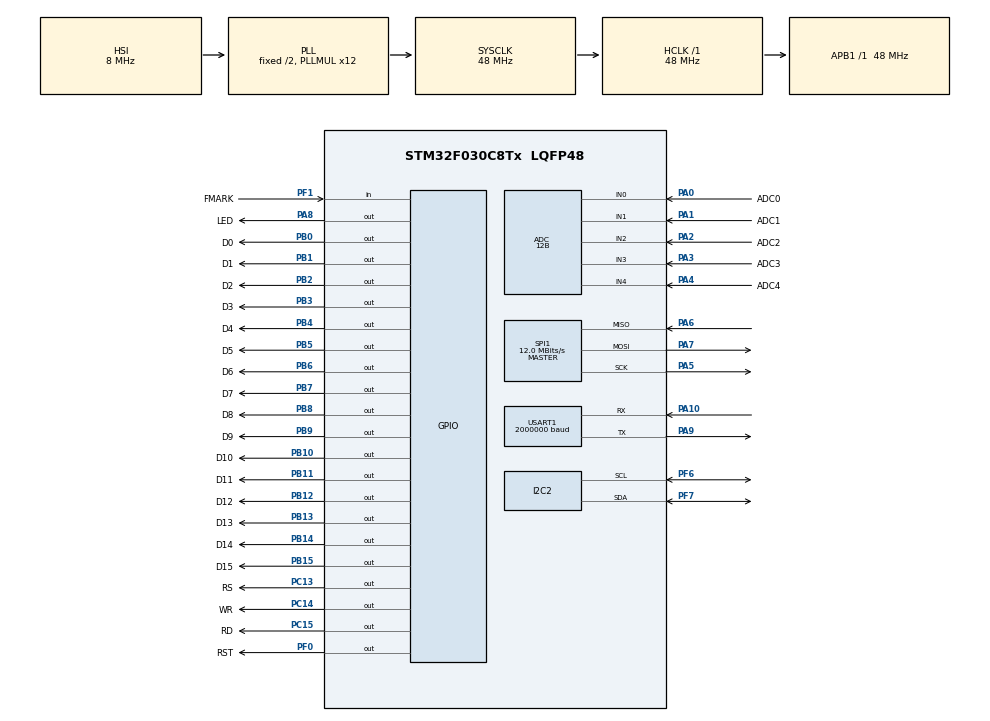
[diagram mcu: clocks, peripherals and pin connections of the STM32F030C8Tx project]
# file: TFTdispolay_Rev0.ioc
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ADC.ClockPrescaler=ADC_CLOCK_ASYNC_DIV1
ADC.ContinuousConvMode=DISABLE
ADC.Resolution=ADC_RESOLUTION_12B
ADC.SamplingTime=ADC_SAMPLETIME_28CYCLES_5
FATFS._FS_TIMEOUT=1000
FATFS._MAX_SS=1024
FATFS._USE_LFN=1
I2C2.Timing=0x20303E5D
Mcu.Family=STM32F0
Mcu.Name=STM32F030C8Tx
Mcu.Package=LQFP48
PA0.GPIO_Label=ADC0
PA0.Mode=IN0
PA0.Signal=ADC_IN0
PA1.GPIO_Label=ADC1
PA1.Mode=IN1
PA1.Signal=ADC_IN1
PA10.GPIO_ModeDefaultPP=GPIO_MODE_AF_PP
PA10.GPIO_PuPd=GPIO_NOPULL
PA10.GPIO_Speed=GPIO_SPEED_FREQ_HIGH
PA10.Mode=Asynchronous
PA10.Signal=USART1_RX
PA13.GPIO_Label=SWDIO
PA13.Signal=SYS_SWDIO
PA2.GPIO_Label=ADC2
PA2.Mode=IN2
PA2.Signal=ADC_IN2
PA3.GPIO_Label=ADC3
PA3.Mode=IN3
PA3.Signal=ADC_IN3
PA4.GPIO_Label=ADC4
PA4.Mode=IN4
PA4.Signal=ADC_IN4
PA5.GPIO_Mode=GPIO_MODE_AF_PP
PA5.GPIO_PuPd=GPIO_NOPULL
PA5.GPIO_Speed=GPIO_SPEED_FREQ_HIGH
PA5.Mode=Full_Duplex_Master
PA5.Signal=SPI1_SCK
PA6.GPIO_Mode=GPIO_MODE_AF_PP
PA6.GPIO_PuPd=GPIO_NOPULL
PA6.GPIO_Speed=GPIO_SPEED_FREQ_HIGH
PA6.Mode=Full_Duplex_Master
PA6.Signal=SPI1_MISO
PA7.GPIO_Mode=GPIO_MODE_AF_PP
PA7.GPIO_PuPd=GPIO_NOPULL
PA7.GPIO_Speed=GPIO_SPEED_FREQ_HIGH
PA7.Mode=Full_Duplex_Master
PA7.Signal=SPI1_MOSI
PA8.GPIO_Label=LED
PA8.GPIO_ModeDefaultOutputPP=GPIO_MODE_OUTPUT_OD
PA8.GPIO_PuPd=GPIO_PULLUP
PA8.GPIO_Speed=GPIO_SPEED_FREQ_HIGH
PA8.PinState=GPIO_PIN_RESET
PA8.Signal=GPIO_Output
PA9.GPIO_ModeDefaultPP=GPIO_MODE_AF_PP
PA9.GPIO_PuPd=GPIO_NOPULL
PA9.GPIO_Speed=GPIO_SPEED_FREQ_HIGH
PA9.Mode=Asynchronous
PA9.Signal=USART1_TX
PB0.GPIO_Label=D0
PB0.GPIO_PuPd=GPIO_NOPULL
PB0.GPIO_Speed=GPIO_SPEED_FREQ_HIGH
PB0.Signal=GPIO_Output
PB1.GPIO_Label=D1
PB1.GPIO_PuPd=GPIO_NOPULL
PB1.GPIO_Speed=GPIO_SPEED_FREQ_HIGH
PB1.Signal=GPIO_Output
PB10.GPIO_Label=D10
PB10.GPIO_ModeDefaultOutputPP=GPIO_MODE_OUTPUT_OD
PB10.GPIO_PuPd=GPIO_NOPULL
PB10.GPIO_Speed=GPIO_SPEED_FREQ_HIGH
PB10.Signal=GPIO_Output
PB11.GPIO_Label=D11
PB11.GPIO_Speed=GPIO_SPEED_FREQ_HIGH
PB11.Signal=GPIO_Output
PB12.GPIO_Label=D12
PB12.GPIO_Speed=GPIO_SPEED_FREQ_HIGH
PB12.Signal=GPIO_Output
PB13.GPIO_Label=D13
PB13.GPIO_Speed=GPIO_SPEED_FREQ_HIGH
PB13.Signal=GPIO_Output
PB14.GPIO_Label=D14
PB14.GPIO_Speed=GPIO_SPEED_FREQ_HIGH
PB14.Signal=GPIO_Output
PB15.GPIO_Label=D15
PB15.GPIO_Speed=GPIO_SPEED_FREQ_HIGH
PB15.Signal=GPIO_Output
PB2.GPIO_Label=D2
PB2.GPIO_PuPd=GPIO_NOPULL
PB2.GPIO_Speed=GPIO_SPEED_FREQ_HIGH
PB2.Signal=GPIO_Output
PB3.GPIO_Label=D3
PB3.GPIO_PuPd=GPIO_NOPULL
PB3.GPIO_Speed=GPIO_SPEED_FREQ_HIGH
PB3.Signal=GPIO_Output
PB4.GPIO_Label=D4
PB4.GPIO_PuPd=GPIO_NOPULL
PB4.GPIO_Speed=GPIO_SPEED_FREQ_HIGH
PB4.Signal=GPIO_Output
PB5.GPIO_Label=D5
PB5.GPIO_PuPd=GPIO_NOPULL
PB5.GPIO_Speed=GPIO_SPEED_FREQ_HIGH
PB5.Signal=GPIO_Output
PB6.GPIO_FM6=__NULL
PB6.GPIO_Label=D6
PB6.GPIO_PuPd=GPIO_NOPULL
PB6.GPIO_Speed=GPIO_SPEED_FREQ_HIGH
PB6.Signal=GPIO_Output
PB7.GPIO_Label=D7
PB7.GPIO_PuPd=GPIO_NOPULL
PB7.GPIO_Speed=GPIO_SPEED_FREQ_HIGH
PB7.Signal=GPIO_Output
PB8.GPIO_Label=D8
PB8.GPIO_PuPd=GPIO_NOPULL
PB8.GPIO_Speed=GPIO_SPEED_FREQ_HIGH
PB8.Signal=GPIO_Output
PB9.GPIO_Label=D9
PB9.GPIO_PuPd=GPIO_NOPULL
PB9.GPIO_Speed=GPIO_SPEED_FREQ_HIGH
PB9.Signal=GPIO_Output
PC13.GPIO_Label=RS
PC13.GPIO_PuPd=GPIO_PULLUP
PC13.Signal=GPIO_Output
PC14-OSC32_IN.GPIO_Label=WR
PC14-OSC32_IN.GPIO_PuPd=GPIO_PULLUP
PC14-OSC32_IN.Signal=GPIO_Output
PC15-OSC32_OUT.GPIO_Label=RD
PC15-OSC32_OUT.GPIO_PuPd=GPIO_PULLUP
PC15-OSC32_OUT.Signal=GPIO_Output
PF0-OSC_IN.GPIO_Label=RST
PF0-OSC_IN.GPIO_PuPd=GPIO_PULLUP
PF0-OSC_IN.GPIO_Speed=GPIO_SPEED_FREQ_HIGH
PF0-OSC_IN.Signal=GPIO_Output
PF1-OSC_OUT.GPIO_Label=FMARK
PF1-OSC_OUT.Signal=GPIO_Input
PF6.Mode=I2C
PF6.Signal=I2C2_SCL
PF7.Mode=I2C
PF7.Signal=I2C2_SDA
ProjectManager.HeapSize=0x200
ProjectManager.StackSize=0x400
ProjectManager.TargetToolchain=STM32CubeIDE
RCC.AHBFreq_Value=48000000
RCC.APB1Freq_Value=48000000
RCC.APB1TimFreq_Value=48000000
RCC.HCLKFreq_Value=48000000
RCC.PLLMUL=RCC_PLL_MUL12
RCC.SYSCLKFreq_VALUE=48000000
RCC.SYSCLKSource=RCC_SYSCLKSOURCE_PLLCLK
SPI1.BaudRatePrescaler=SPI_BAUDRATEPRESCALER_4
SPI1.CalculateBaudRate=12.0 MBits/s
SPI1.DataSize=SPI_DATASIZE_8BIT
SPI1.Direction=SPI_DIRECTION_2LINES
SPI1.Mode=SPI_MODE_MASTER
SPI1.VirtualType=VM_MASTER
USART1.BaudRate=2000000
USART1.OverrunDisableParam=ADVFEATURE_OVERRUN_DISABLE
USART1.VirtualMode-Asynchronous=VM_ASYNC
VP_FATFS_VS_Generic.Mode=User_defined
board=custom

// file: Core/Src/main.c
/* USER CODE BEGIN Header */
/**
  ******************************************************************************
  * @file           : main.c
  * @brief          : Main program body
  ******************************************************************************
  * @attention
  *
  * Copyright (c) 2023 STMicroelectronics.
  * All rights reserved.
  *
  * This software is licensed under terms that can be found in the LICENSE file
  * in the root directory of this software component.
  * If no LICENSE file comes with this software, it is provided AS-IS.
  *
  ******************************************************************************
  */
/* USER CODE END Header */
#include "main.h"
#include "fatfs.h"

/* USER CODE BEGIN Includes */
#include "app.h"
/* USER CODE END Includes */

ADC_HandleTypeDef hadc;

I2C_HandleTypeDef hi2c2;

SPI_HandleTypeDef hspi1;

UART_HandleTypeDef huart1;

void SystemClock_Config(void);
static void MX_GPIO_Init(void);
static void MX_ADC_Init(void);
static void MX_SPI1_Init(void);
static void MX_USART1_UART_Init(void);
static void MX_I2C2_Init(void);

int main(void)
{

  /* MCU Configuration--------------------------------------------------------*/

  /* Reset of all peripherals, Initializes the Flash interface and the Systick. */
  HAL_Init();

  /* Configure the system clock */
  SystemClock_Config();

  /* Initialize all configured peripherals */
  MX_GPIO_Init();
  MX_ADC_Init();
  MX_SPI1_Init();
  MX_USART1_UART_Init();
  MX_FATFS_Init();
  MX_I2C2_Init();
  /* USER CODE BEGIN 2 */

	HAL_GPIO_WritePin(LED_GPIO_Port, LED_Pin, GPIO_PIN_RESET);
	HAL_Delay(200);
	HAL_GPIO_WritePin(LED_GPIO_Port, LED_Pin, GPIO_PIN_SET);
	HAL_Delay(200);
	HAL_GPIO_WritePin(LED_GPIO_Port, LED_Pin, GPIO_PIN_RESET);
	HAL_Delay(200);
	HAL_GPIO_WritePin(LED_GPIO_Port, LED_Pin, GPIO_PIN_SET);
	HAL_Delay(200);

	app_init();
	app_loop();

  /* USER CODE END 2 */

  /* Infinite loop */
  while (1)
  {

  }
}

void SystemClock_Config(void)
{
  RCC_OscInitTypeDef RCC_OscInitStruct = {0};
  RCC_ClkInitTypeDef RCC_ClkInitStruct = {0};
  RCC_PeriphCLKInitTypeDef PeriphClkInit = {0};

  /** Initializes the RCC Oscillators according to the specified parameters
  * in the RCC_OscInitTypeDef structure.
  */
  RCC_OscInitStruct.OscillatorType = RCC_OSCILLATORTYPE_HSI|RCC_OSCILLATORTYPE_HSI14;
  RCC_OscInitStruct.HSIState = RCC_HSI_ON;
  RCC_OscInitStruct.HSI14State = RCC_HSI14_ON;
  RCC_OscInitStruct.HSICalibrationValue = RCC_HSICALIBRATION_DEFAULT;
  RCC_OscInitStruct.HSI14CalibrationValue = 16;
  RCC_OscInitStruct.PLL.PLLState = RCC_PLL_ON;
  RCC_OscInitStruct.PLL.PLLSource = RCC_PLLSOURCE_HSI;
  RCC_OscInitStruct.PLL.PLLMUL = RCC_PLL_MUL12;
  RCC_OscInitStruct.PLL.PREDIV = RCC_PREDIV_DIV1;
  if (HAL_RCC_OscConfig(&RCC_OscInitStruct) != HAL_OK)
  {
    Error_Handler();
  }

  /** Initializes the CPU, AHB and APB buses clocks
  */
  RCC_ClkInitStruct.ClockType = RCC_CLOCKTYPE_HCLK|RCC_CLOCKTYPE_SYSCLK
                              |RCC_CLOCKTYPE_PCLK1;
  RCC_ClkInitStruct.SYSCLKSource = RCC_SYSCLKSOURCE_PLLCLK;
  RCC_ClkInitStruct.AHBCLKDivider = RCC_SYSCLK_DIV1;
  RCC_ClkInitStruct.APB1CLKDivider = RCC_HCLK_DIV1;

  if (HAL_RCC_ClockConfig(&RCC_ClkInitStruct, FLASH_LATENCY_1) != HAL_OK)
  {
    Error_Handler();
  }
  PeriphClkInit.PeriphClockSelection = RCC_PERIPHCLK_USART1;
  PeriphClkInit.Usart1ClockSelection = RCC_USART1CLKSOURCE_PCLK1;
  if (HAL_RCCEx_PeriphCLKConfig(&PeriphClkInit) != HAL_OK)
  {
    Error_Handler();
  }
}

static void MX_ADC_Init(void)
{

  ADC_ChannelConfTypeDef sConfig = {0};

  /** Configure the global features of the ADC (Clock, Resolution, Data Alignment and number of conversion)
  */
  hadc.Instance = ADC1;
  hadc.Init.ClockPrescaler = ADC_CLOCK_ASYNC_DIV1;
  hadc.Init.Resolution = ADC_RESOLUTION_12B;
  hadc.Init.DataAlign = ADC_DATAALIGN_RIGHT;
  hadc.Init.ScanConvMode = ADC_SCAN_DIRECTION_FORWARD;
  hadc.Init.EOCSelection = ADC_EOC_SINGLE_CONV;
  hadc.Init.LowPowerAutoWait = DISABLE;
  hadc.Init.LowPowerAutoPowerOff = DISABLE;
  hadc.Init.ContinuousConvMode = DISABLE;
  hadc.Init.DiscontinuousConvMode = DISABLE;
  hadc.Init.ExternalTrigConv = ADC_SOFTWARE_START;
  hadc.Init.ExternalTrigConvEdge = ADC_EXTERNALTRIGCONVEDGE_NONE;
  hadc.Init.DMAContinuousRequests = DISABLE;
  hadc.Init.Overrun = ADC_OVR_DATA_PRESERVED;
  if (HAL_ADC_Init(&hadc) != HAL_OK)
  {
    Error_Handler();
  }

  /** Configure for the selected ADC regular channel to be converted.
  */
  sConfig.Channel = ADC_CHANNEL_0;
  sConfig.Rank = ADC_RANK_CHANNEL_NUMBER;
  sConfig.SamplingTime = ADC_SAMPLETIME_28CYCLES_5;
  if (HAL_ADC_ConfigChannel(&hadc, &sConfig) != HAL_OK)
  {
    Error_Handler();
  }

  /** Configure for the selected ADC regular channel to be converted.
  */
  sConfig.Channel = ADC_CHANNEL_1;
  if (HAL_ADC_ConfigChannel(&hadc, &sConfig) != HAL_OK)
  {
    Error_Handler();
  }

  /** Configure for the selected ADC regular channel to be converted.
  */
  sConfig.Channel = ADC_CHANNEL_2;
  if (HAL_ADC_ConfigChannel(&hadc, &sConfig) != HAL_OK)
  {
    Error_Handler();
  }

  /** Configure for the selected ADC regular channel to be converted.
  */
  sConfig.Channel = ADC_CHANNEL_3;
  if (HAL_ADC_ConfigChannel(&hadc, &sConfig) != HAL_OK)
  {
    Error_Handler();
  }

  /** Configure for the selected ADC regular channel to be converted.
  */
  sConfig.Channel = ADC_CHANNEL_4;
  if (HAL_ADC_ConfigChannel(&hadc, &sConfig) != HAL_OK)
  {
    Error_Handler();
  }

}

static void MX_I2C2_Init(void)
{

  hi2c2.Instance = I2C2;
  hi2c2.Init.Timing = 0x20303E5D;
  hi2c2.Init.OwnAddress1 = 0;
  hi2c2.Init.AddressingMode = I2C_ADDRESSINGMODE_7BIT;
  hi2c2.Init.DualAddressMode = I2C_DUALADDRESS_DISABLE;
  hi2c2.Init.OwnAddress2 = 0;
  hi2c2.Init.OwnAddress2Masks = I2C_OA2_NOMASK;
  hi2c2.Init.GeneralCallMode = I2C_GENERALCALL_DISABLE;
  hi2c2.Init.NoStretchMode = I2C_NOSTRETCH_DISABLE;
  if (HAL_I2C_Init(&hi2c2) != HAL_OK)
  {
    Error_Handler();
  }

  /** Configure Analogue filter
  */
  if (HAL_I2CEx_ConfigAnalogFilter(&hi2c2, I2C_ANALOGFILTER_ENABLE) != HAL_OK)
  {
    Error_Handler();
  }

  /** Configure Digital filter
  */
  if (HAL_I2CEx_ConfigDigitalFilter(&hi2c2, 0) != HAL_OK)
  {
    Error_Handler();
  }

}

static void MX_SPI1_Init(void)
{

  /* SPI1 parameter configuration*/
  hspi1.Instance = SPI1;
  hspi1.Init.Mode = SPI_MODE_MASTER;
  hspi1.Init.Direction = SPI_DIRECTION_2LINES;
  hspi1.Init.DataSize = SPI_DATASIZE_8BIT;
  hspi1.Init.CLKPolarity = SPI_POLARITY_LOW;
  hspi1.Init.CLKPhase = SPI_PHASE_1EDGE;
  hspi1.Init.NSS = SPI_NSS_SOFT;
  hspi1.Init.BaudRatePrescaler = SPI_BAUDRATEPRESCALER_4;
  hspi1.Init.FirstBit = SPI_FIRSTBIT_MSB;
  hspi1.Init.TIMode = SPI_TIMODE_DISABLE;
  hspi1.Init.CRCCalculation = SPI_CRCCALCULATION_DISABLE;
  hspi1.Init.CRCPolynomial = 7;
  hspi1.Init.CRCLength = SPI_CRC_LENGTH_DATASIZE;
  hspi1.Init.NSSPMode = SPI_NSS_PULSE_ENABLE;
  if (HAL_SPI_Init(&hspi1) != HAL_OK)
  {
    Error_Handler();
  }

}

static void MX_USART1_UART_Init(void)
{

  huart1.Instance = USART1;
  huart1.Init.BaudRate = 2000000;
  huart1.Init.WordLength = UART_WORDLENGTH_8B;
  huart1.Init.StopBits = UART_STOPBITS_1;
  huart1.Init.Parity = UART_PARITY_NONE;
  huart1.Init.Mode = UART_MODE_TX_RX;
  huart1.Init.HwFlowCtl = UART_HWCONTROL_NONE;
  huart1.Init.OverSampling = UART_OVERSAMPLING_16;
  huart1.Init.OneBitSampling = UART_ONE_BIT_SAMPLE_DISABLE;
  huart1.AdvancedInit.AdvFeatureInit = UART_ADVFEATURE_RXOVERRUNDISABLE_INIT;
  huart1.AdvancedInit.OverrunDisable = UART_ADVFEATURE_OVERRUN_DISABLE;
  if (HAL_UART_Init(&huart1) != HAL_OK)
  {
    Error_Handler();
  }

}

static void MX_GPIO_Init(void)
{
  GPIO_InitTypeDef GPIO_InitStruct = {0};

  /* GPIO Ports Clock Enable */
  __HAL_RCC_GPIOC_CLK_ENABLE();
  __HAL_RCC_GPIOF_CLK_ENABLE();
  __HAL_RCC_GPIOA_CLK_ENABLE();
  __HAL_RCC_GPIOB_CLK_ENABLE();

  /*Configure GPIO pin Output Level */
  HAL_GPIO_WritePin(GPIOC, RS_Pin|WR_Pin|RD_Pin, GPIO_PIN_RESET);

  /*Configure GPIO pin Output Level */
  HAL_GPIO_WritePin(RST_GPIO_Port, RST_Pin, GPIO_PIN_RESET);

  /*Configure GPIO pin Output Level */
  HAL_GPIO_WritePin(GPIOB, D0_Pin|D1_Pin|D2_Pin|D10_Pin
                          |D11_Pin|D12_Pin|D13_Pin|D14_Pin
                          |D15_Pin|D3_Pin|D4_Pin|D5_Pin
                          |D6_Pin|D7_Pin|D8_Pin|D9_Pin, GPIO_PIN_RESET);

  /*Configure GPIO pin Output Level */
  HAL_GPIO_WritePin(LED_GPIO_Port, LED_Pin, GPIO_PIN_RESET);

  /*Configure GPIO pins : RS_Pin WR_Pin RD_Pin */
  GPIO_InitStruct.Pin = RS_Pin|WR_Pin|RD_Pin;
  GPIO_InitStruct.Mode = GPIO_MODE_OUTPUT_PP;
  GPIO_InitStruct.Pull = GPIO_PULLUP;
  GPIO_InitStruct.Speed = GPIO_SPEED_FREQ_LOW;
  HAL_GPIO_Init(GPIOC, &GPIO_InitStruct);

  /*Configure GPIO pin : RST_Pin */
  GPIO_InitStruct.Pin = RST_Pin;
  GPIO_InitStruct.Mode = GPIO_MODE_OUTPUT_PP;
  GPIO_InitStruct.Pull = GPIO_PULLUP;
  GPIO_InitStruct.Speed = GPIO_SPEED_FREQ_HIGH;
  HAL_GPIO_Init(RST_GPIO_Port, &GPIO_InitStruct);

  /*Configure GPIO pin : FMARK_Pin */
  GPIO_InitStruct.Pin = FMARK_Pin;
  GPIO_InitStruct.Mode = GPIO_MODE_INPUT;
  GPIO_InitStruct.Pull = GPIO_NOPULL;
  HAL_GPIO_Init(FMARK_GPIO_Port, &GPIO_InitStruct);

  /*Configure GPIO pins : D0_Pin D1_Pin D2_Pin D11_Pin
                           D12_Pin D13_Pin D14_Pin D15_Pin
                           D3_Pin D4_Pin D5_Pin D6_Pin
                           D7_Pin D8_Pin D9_Pin */
  GPIO_InitStruct.Pin = D0_Pin|D1_Pin|D2_Pin|D11_Pin
                          |D12_Pin|D13_Pin|D14_Pin|D15_Pin
                          |D3_Pin|D4_Pin|D5_Pin|D6_Pin
                          |D7_Pin|D8_Pin|D9_Pin;
  GPIO_InitStruct.Mode = GPIO_MODE_OUTPUT_PP;
  GPIO_InitStruct.Pull = GPIO_NOPULL;
  GPIO_InitStruct.Speed = GPIO_SPEED_FREQ_HIGH;
  HAL_GPIO_Init(GPIOB, &GPIO_InitStruct);

  /*Configure GPIO pin : D10_Pin */
  GPIO_InitStruct.Pin = D10_Pin;
  GPIO_InitStruct.Mode = GPIO_MODE_OUTPUT_OD;
  GPIO_InitStruct.Pull = GPIO_NOPULL;
  GPIO_InitStruct.Speed = GPIO_SPEED_FREQ_HIGH;
  HAL_GPIO_Init(D10_GPIO_Port, &GPIO_InitStruct);

  /*Configure GPIO pin : LED_Pin */
  GPIO_InitStruct.Pin = LED_Pin;
  GPIO_InitStruct.Mode = GPIO_MODE_OUTPUT_OD;
  GPIO_InitStruct.Pull = GPIO_PULLUP;
  GPIO_InitStruct.Speed = GPIO_SPEED_FREQ_HIGH;
  HAL_GPIO_Init(LED_GPIO_Port, &GPIO_InitStruct);

}

void Error_Handler(void)
{
  __disable_irq();
  while (1)
  {
  }
}
